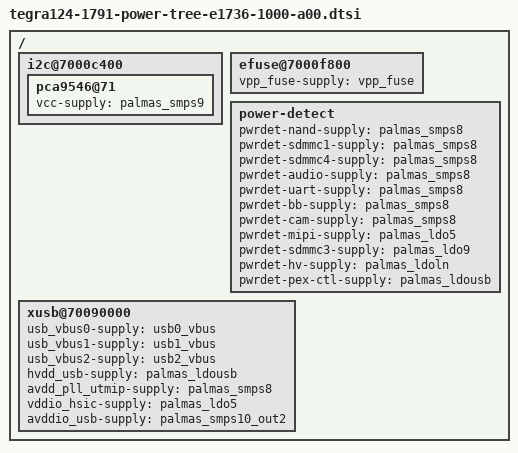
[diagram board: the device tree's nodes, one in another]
#include "tegra124-platforms/tegra124-e1791-e1736-pmic.dtsi"
#include "tegra124-platforms/tegra124-tn8-fixed-e1736-1000-a00.dtsi"

/ {
	i2c@7000c400 {
		pca9546@71 {
			vcc-supply = <&palmas_smps9>;
		};  
	};  

	/* Populate fuse supply */
	efuse@7000f800 {
		vpp_fuse-supply = <&vpp_fuse>;
	};

	power-detect {
		pwrdet-nand-supply = <&palmas_smps8>;
		pwrdet-sdmmc1-supply = <&palmas_smps8>;
		pwrdet-sdmmc4-supply = <&palmas_smps8>;
		pwrdet-audio-supply = <&palmas_smps8>;
		pwrdet-uart-supply = <&palmas_smps8>;
		pwrdet-bb-supply = <&palmas_smps8>;
		pwrdet-cam-supply = <&palmas_smps8>;
		pwrdet-mipi-supply = <&palmas_ldo5>;
		pwrdet-sdmmc3-supply = <&palmas_ldo9>;
		pwrdet-hv-supply = <&palmas_ldoln>;
		pwrdet-pex-ctl-supply = <&palmas_ldousb>;
	};

	xusb@70090000 {
		usb_vbus0-supply = <&usb0_vbus>;
		usb_vbus1-supply = <&usb1_vbus>;
		usb_vbus2-supply = <&usb2_vbus>;
		hvdd_usb-supply = <&palmas_ldousb>;
		avdd_pll_utmip-supply = <&palmas_smps8>;
		vddio_hsic-supply = <&palmas_ldo5>;
		avddio_usb-supply = <&palmas_smps10_out2>;
	};
};
